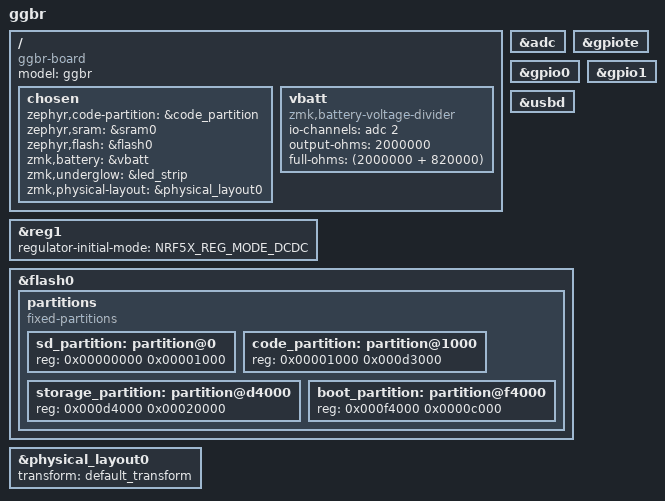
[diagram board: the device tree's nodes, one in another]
/*
 * Copyright (c) 2025 Naomi233
 *
 * SPDX-License-Identifier: MIT
 */

/dts-v1/;

#include <nordic/nrf52840_qiaa.dtsi>
#include <common/nordic/nrf52840_uf2_boot_mode.dtsi>

#include <dt-bindings/led/led.h>
#include <dt-bindings/zmk/matrix_transform.h>

#include "ggbr-pinctrl.dtsi"
#include "ggbr-layouts.dtsi"

/ {
    model = "ggbr";
    compatible = "ggbr-board";

    chosen {
        zephyr,code-partition = &code_partition;
        zephyr,sram = &sram0;
        zephyr,flash = &flash0;
        zmk,battery = &vbatt;
        zmk,underglow = &led_strip;
        zmk,physical-layout = &physical_layout0;
    };

    vbatt: vbatt {
        compatible = "zmk,battery-voltage-divider";
        io-channels = <&adc 2>;
        output-ohms = <2000000>;
        full-ohms = <(2000000 + 820000)>;
    };
};

&reg1 {
    regulator-initial-mode = <NRF5X_REG_MODE_DCDC>;
};

&adc {
    status = "okay";
};

&gpiote {
    status = "okay";
};

&gpio0 {
    status = "okay";
};

&gpio1 {
    status = "okay";
};

zephyr_udc0: &usbd {
    status = "okay";
};

&flash0 {
    /*
     * For more information, see:
     * http://docs.zephyrproject.org/latest/devices/dts/flash_partitions.html
     */
    partitions {
        compatible = "fixed-partitions";
        #address-cells = <1>;
        #size-cells = <1>;

        sd_partition: partition@0 {
            reg = <0x00000000 0x00001000>;
        };

        code_partition: partition@1000 {
            reg = <0x00001000 0x000d3000>;
        };

        /*
         * The flash starting at 0x000d4000 and ending at
         * 0x000f3fff is reserved for use by the application.
         */

        /*
         * Storage partition will be used by FCB/LittleFS/NVS
         * if enabled.
         */
        storage_partition: partition@d4000 {
            reg = <0x000d4000 0x00020000>;
        };

        boot_partition: partition@f4000 {
            reg = <0x000f4000 0x0000c000>;
        };
    };
};

&physical_layout0 {
    transform = <&default_transform>;
};
